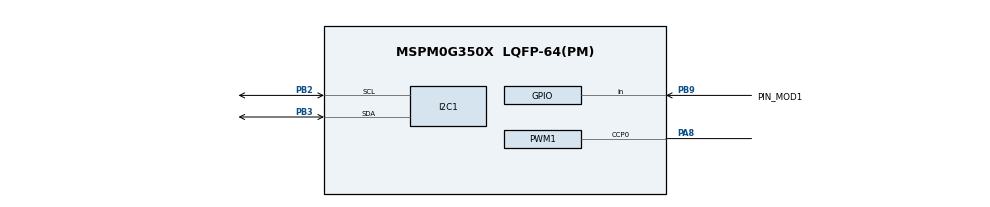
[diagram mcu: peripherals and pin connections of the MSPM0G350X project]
/**
 * @cliArgs --device "MSPM0G350X" --package "LQFP-64(PM)" --part "Default" --product "mspm0_sdk@2.01.00.03"
 * @versions {"tool":"1.20.0+3587"}
 */

/**
 * Import the modules used in this configuration.
 */
const GPIO   = scripting.addModule("/ti/driverlib/GPIO", {}, false);
const GPIO1  = GPIO.addInstance();
const GPIO2  = GPIO.addInstance();
const GPIO3  = GPIO.addInstance();
const GPIO4  = GPIO.addInstance();
const GPIO5  = GPIO.addInstance();
const GPIO6  = GPIO.addInstance();
const I2C    = scripting.addModule("/ti/driverlib/I2C", {}, false);
const I2C1   = I2C.addInstance();
const PWM    = scripting.addModule("/ti/driverlib/PWM", {}, false);
const PWM1   = PWM.addInstance();
const SYSCTL = scripting.addModule("/ti/driverlib/SYSCTL");
const TIMER  = scripting.addModule("/ti/driverlib/TIMER", {}, false);
const TIMER1 = TIMER.addInstance();
const UART   = scripting.addModule("/ti/driverlib/UART", {}, false);
const UART1  = UART.addInstance();

/**
 * Write custom configuration values to the imported modules.
 */
GPIO1.$name                          = "GPIO_OLED";
GPIO1.associatedPins.create(2);
GPIO1.associatedPins[0].$name        = "PIN_SCL";
GPIO1.associatedPins[0].assignedPort = "PORTA";
GPIO1.associatedPins[0].assignedPin  = "12";
GPIO1.associatedPins[1].$name        = "PIN_SDA";
GPIO1.associatedPins[1].assignedPort = "PORTA";
GPIO1.associatedPins[1].assignedPin  = "13";

const Board = scripting.addModule("/ti/driverlib/Board", {}, false);

GPIO2.$name                          = "GPIO_sheng";
GPIO2.associatedPins[0].$name        = "PIN_0";
GPIO2.associatedPins[0].assignedPort = "PORTB";
GPIO2.associatedPins[0].assignedPin  = "4";

GPIO3.$name                          = "GPIO_guang";
GPIO3.associatedPins[0].$name        = "PIN_1";
GPIO3.associatedPins[0].assignedPin  = "1";
GPIO3.associatedPins[0].assignedPort = "PORTB";

GPIO4.$name                          = "GPIO_huidu";
GPIO4.associatedPins.create(7);
GPIO4.associatedPins[0].$name        = "PIN_l3";
GPIO4.associatedPins[0].direction    = "INPUT";
GPIO4.associatedPins[0].assignedPort = "PORTA";
GPIO4.associatedPins[0].assignedPin  = "25";
GPIO4.associatedPins[0].polarity     = "RISE";
GPIO4.associatedPins[0].pubChanID    = 5;
GPIO4.associatedPins[1].$name        = "PIN_l2";
GPIO4.associatedPins[1].direction    = "INPUT";
GPIO4.associatedPins[1].assignedPort = "PORTA";
GPIO4.associatedPins[1].assignedPin  = "27";
GPIO4.associatedPins[1].polarity     = "RISE";
GPIO4.associatedPins[1].pubChanID    = 5;
GPIO4.associatedPins[2].$name        = "PIN_l1";
GPIO4.associatedPins[2].direction    = "INPUT";
GPIO4.associatedPins[2].assignedPort = "PORTA";
GPIO4.associatedPins[2].assignedPin  = "24";
GPIO4.associatedPins[2].polarity     = "RISE";
GPIO4.associatedPins[2].pubChanID    = 5;
GPIO4.associatedPins[3].$name        = "PIN_m";
GPIO4.associatedPins[3].direction    = "INPUT";
GPIO4.associatedPins[3].assignedPort = "PORTA";
GPIO4.associatedPins[3].assignedPin  = "17";
GPIO4.associatedPins[3].pubChanID    = 5;
GPIO4.associatedPins[3].polarity     = "RISE";
GPIO4.associatedPins[4].$name        = "PIN_r1";
GPIO4.associatedPins[4].direction    = "INPUT";
GPIO4.associatedPins[4].assignedPort = "PORTA";
GPIO4.associatedPins[4].polarity     = "RISE";
GPIO4.associatedPins[4].pubChanID    = 5;
GPIO4.associatedPins[4].assignedPin  = "31";
GPIO4.associatedPins[5].$name        = "PIN_r2";
GPIO4.associatedPins[5].direction    = "INPUT";
GPIO4.associatedPins[5].assignedPort = "PORTA";
GPIO4.associatedPins[5].polarity     = "RISE";
GPIO4.associatedPins[5].assignedPin  = "18";
GPIO4.associatedPins[5].pubChanID    = 5;
GPIO4.associatedPins[6].$name        = "PIN_r3";
GPIO4.associatedPins[6].direction    = "INPUT";
GPIO4.associatedPins[6].assignedPort = "PORTA";
GPIO4.associatedPins[6].assignedPin  = "28";
GPIO4.associatedPins[6].polarity     = "RISE";
GPIO4.associatedPins[6].pubChanID    = 5;

GPIO5.$name                          = "GPIO_Encoder";
GPIO5.associatedPins.create(2);
GPIO5.associatedPins[0].direction    = "INPUT";
GPIO5.associatedPins[0].$name        = "L_A";
GPIO5.associatedPins[0].assignedPort = "PORTB";
GPIO5.associatedPins[0].assignedPin  = "7";
GPIO5.associatedPins[0].interruptEn  = true;
GPIO5.associatedPins[0].polarity     = "RISE";
GPIO5.associatedPins[1].$name        = "R_A";
GPIO5.associatedPins[1].direction    = "INPUT";
GPIO5.associatedPins[1].assignedPort = "PORTB";
GPIO5.associatedPins[1].assignedPin  = "24";
GPIO5.associatedPins[1].interruptEn  = true;
GPIO5.associatedPins[1].polarity     = "RISE";

GPIO6.$name                              = "GPIO_BUTTON";
GPIO6.associatedPins.create(5);
GPIO6.associatedPins[0].direction        = "INPUT";
GPIO6.associatedPins[0].$name            = "PIN_MOD1";
GPIO6.associatedPins[0].internalResistor = "PULL_DOWN";
GPIO6.associatedPins[0].assignedPort     = "PORTB";
GPIO6.associatedPins[0].assignedPin      = "9";
GPIO6.associatedPins[0].pin.$assign      = "PB9";
GPIO6.associatedPins[1].direction        = "INPUT";
GPIO6.associatedPins[1].$name            = "PIN_MOD2";
GPIO6.associatedPins[1].internalResistor = "PULL_DOWN";
GPIO6.associatedPins[1].assignedPort     = "PORTB";
GPIO6.associatedPins[1].assignedPin      = "13";
GPIO6.associatedPins[2].$name            = "PIN_MOD3";
GPIO6.associatedPins[2].direction        = "INPUT";
GPIO6.associatedPins[2].internalResistor = "PULL_DOWN";
GPIO6.associatedPins[2].assignedPort     = "PORTB";
GPIO6.associatedPins[2].assignedPin      = "15";
GPIO6.associatedPins[3].$name            = "PIN_MOD4";
GPIO6.associatedPins[3].direction        = "INPUT";
GPIO6.associatedPins[3].internalResistor = "PULL_DOWN";
GPIO6.associatedPins[3].assignedPort     = "PORTB";
GPIO6.associatedPins[3].assignedPin      = "16";
GPIO6.associatedPins[4].$name            = "PIN_GO";
GPIO6.associatedPins[4].direction        = "INPUT";
GPIO6.associatedPins[4].assignedPort     = "PORTB";
GPIO6.associatedPins[4].assignedPin      = "8";
GPIO6.associatedPins[4].internalResistor = "PULL_DOWN";

I2C1.$name                             = "I2C_MPU6050";
I2C1.basicEnableController             = true;
I2C1.intController                     = ["ARBITRATION_LOST","NACK","RXFIFO_TRIGGER","RX_DONE","TX_DONE"];
I2C1.interruptPriority                 = "0";
I2C1.peripheral.sdaPin.$assign         = "PB3";
I2C1.peripheral.sclPin.$assign         = "PB2";
I2C1.sdaPinConfig.hideOutputInversion  = scripting.forceWrite(false);
I2C1.sdaPinConfig.onlyInternalResistor = scripting.forceWrite(false);
I2C1.sdaPinConfig.passedPeripheralType = scripting.forceWrite("Digital");
I2C1.sdaPinConfig.$name                = "ti_driverlib_gpio_GPIOPinGeneric2";
I2C1.sclPinConfig.hideOutputInversion  = scripting.forceWrite(false);
I2C1.sclPinConfig.onlyInternalResistor = scripting.forceWrite(false);
I2C1.sclPinConfig.passedPeripheralType = scripting.forceWrite("Digital");
I2C1.sclPinConfig.$name                = "ti_driverlib_gpio_GPIOPinGeneric3";

PWM1.$name                      = "PWM_0";
PWM1.clockPrescale              = 256;
PWM1.interrupts                 = ["CC0_DN_EVENT"];
PWM1.peripheral.ccp0Pin.$assign = "PA8";
PWM1.PWM_CHANNEL_0.$name        = "ti_driverlib_pwm_PWMTimerCC0";
PWM1.PWM_CHANNEL_0.dutyCycle    = 1;
PWM1.PWM_CHANNEL_1.$name        = "ti_driverlib_pwm_PWMTimerCC1";
PWM1.PWM_CHANNEL_1.dutyCycle    = 1;
PWM1.ccp0PinConfig.$name        = "ti_driverlib_gpio_GPIOPinGeneric0";
PWM1.ccp1PinConfig.$name        = "ti_driverlib_gpio_GPIOPinGeneric1";

SYSCTL.forceDefaultClkConfig = true;

TIMER1.$name              = "TIMER_1s";
TIMER1.timerClkPrescale   = 256;
TIMER1.timerStartTimer    = true;
TIMER1.timerMode          = "PERIODIC";
TIMER1.timerClkDiv        = 8;
TIMER1.interrupts         = ["ZERO"];
TIMER1.interruptPriority  = "1";
TIMER1.timerPeriod        = "20 ms";
TIMER1.peripheral.$assign = "TIMG0";

UART1.$name             = "UART_0";
UART1.uartClkSrc        = "LFCLK";
UART1.ovsRate           = "3";
UART1.enableFIFO        = true;
UART1.rxFifoThreshold   = "DL_UART_RX_FIFO_LEVEL_ONE_ENTRY";
UART1.enableDMARX       = false;
UART1.enableDMATX       = false;
UART1.enabledInterrupts = ["RX"];
UART1.interruptPriority = "1";
UART1.txPinConfig.$name = "ti_driverlib_gpio_GPIOPinGeneric4";
UART1.rxPinConfig.$name = "ti_driverlib_gpio_GPIOPinGeneric5";

/**
 * Pinmux solution for unlocked pins/peripherals. This ensures that minor changes to the automatic solver in a future
 * version of the tool will not impact the pinmux you originally saw.  These lines can be completely deleted in order to
 * re-solve from scratch.
 */
GPIO1.associatedPins[0].pin.$suggestSolution = "PA12";
GPIO1.associatedPins[1].pin.$suggestSolution = "PA13";
Board.peripheral.$suggestSolution            = "DEBUGSS";
Board.peripheral.swclkPin.$suggestSolution   = "PA20";
Board.peripheral.swdioPin.$suggestSolution   = "PA19";
GPIO2.associatedPins[0].pin.$suggestSolution = "PB4";
GPIO3.associatedPins[0].pin.$suggestSolution = "PB1";
GPIO4.associatedPins[0].pin.$suggestSolution = "PA25";
GPIO4.associatedPins[1].pin.$suggestSolution = "PA27";
GPIO4.associatedPins[2].pin.$suggestSolution = "PA24";
GPIO4.associatedPins[3].pin.$suggestSolution = "PA17";
GPIO4.associatedPins[4].pin.$suggestSolution = "PA31";
GPIO4.associatedPins[5].pin.$suggestSolution = "PA18";
GPIO4.associatedPins[6].pin.$suggestSolution = "PA28";
GPIO5.associatedPins[0].pin.$suggestSolution = "PB7";
GPIO5.associatedPins[1].pin.$suggestSolution = "PB24";
GPIO6.associatedPins[1].pin.$suggestSolution = "PB13";
GPIO6.associatedPins[2].pin.$suggestSolution = "PB15";
GPIO6.associatedPins[3].pin.$suggestSolution = "PB16";
GPIO6.associatedPins[4].pin.$suggestSolution = "PB8";
I2C1.peripheral.$suggestSolution             = "I2C1";
PWM1.peripheral.$suggestSolution             = "TIMA0";
PWM1.peripheral.ccp1Pin.$suggestSolution     = "PA22";
SYSCTL.peripheral.$suggestSolution           = "SYSCTL";
UART1.peripheral.$suggestSolution            = "UART0";
UART1.peripheral.rxPin.$suggestSolution      = "PA1";
UART1.peripheral.txPin.$suggestSolution      = "PA0";
